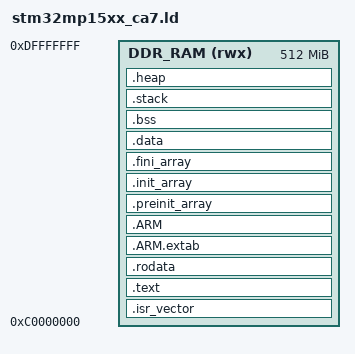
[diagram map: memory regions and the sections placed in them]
/* Linker script for STM32MP15 Cortex-A7 */
MEMORY
{
    DDR_RAM (rwx) : ORIGIN = 0xC0000000, LENGTH = 512M
}

ENTRY(Reset_Handler)

SECTIONS
{
    .isr_vector :
    {
        . = ALIGN(4);
        KEEP(*(.isr_vector))
        . = ALIGN(4);
    } > DDR_RAM

    .text :
    {
        . = ALIGN(4);
        *(.text)
        *(.text*)
        *(.glue_7)
        *(.glue_7t)
        *(.eh_frame)
        KEEP (*(.init))
        KEEP (*(.fini))
        . = ALIGN(4);
        _etext = .;
    } > DDR_RAM

    .rodata :
    {
        . = ALIGN(4);
        *(.rodata)
        *(.rodata*)
        . = ALIGN(4);
    } > DDR_RAM

    .ARM.extab :
    {
        . = ALIGN(4);
        *(.ARM.extab* .gnu.linkonce.armextab.*)
        . = ALIGN(4);
    } > DDR_RAM

    .ARM :
    {
        . = ALIGN(4);
        __exidx_start = .;
        *(.ARM.exidx* .gnu.linkonce.armexidx.*)
        __exidx_end = .;
        . = ALIGN(4);
    } > DDR_RAM

    .preinit_array :
    {
        . = ALIGN(4);
        PROVIDE_HIDDEN (__preinit_array_start = .);
        KEEP (*(.preinit_array*))
        PROVIDE_HIDDEN (__preinit_array_end = .);
        . = ALIGN(4);
    } > DDR_RAM

    .init_array :
    {
        . = ALIGN(4);
        PROVIDE_HIDDEN (__init_array_start = .);
        KEEP (*(SORT(.init_array.*)))
        KEEP (*(.init_array*))
        PROVIDE_HIDDEN (__init_array_end = .);
        . = ALIGN(4);
    } > DDR_RAM

    .fini_array :
    {
        . = ALIGN(4);
        PROVIDE_HIDDEN (__fini_array_start = .);
        KEEP (*(SORT(.fini_array.*)))
        KEEP (*(.fini_array*))
        PROVIDE_HIDDEN (__fini_array_end = .);
        . = ALIGN(4);
    } > DDR_RAM

    .data :
    {
        . = ALIGN(4);
        _sdata = .;
        *(.data)
        *(.data*)
        . = ALIGN(4);
        _edata = .;
    } > DDR_RAM

    .bss :
    {
        . = ALIGN(4);
        _sbss = .;
        *(.bss)
        *(.bss*)
        *(COMMON)
        . = ALIGN(4);
        _ebss = .;
    } > DDR_RAM

    .stack :
    {
        . = ALIGN(8);
        *(.stack)
    } > DDR_RAM

    .heap :
    {
        . = ALIGN(8);
        __heap_start__ = .;
        . = . + 0x800000;
        __heap_end__ = .;
    } > DDR_RAM

    /* Remove information from the standard libraries */
    /DISCARD/ :
    {
        libc.a ( * )
        libm.a ( * )
        libgcc.a ( * )
    }
}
